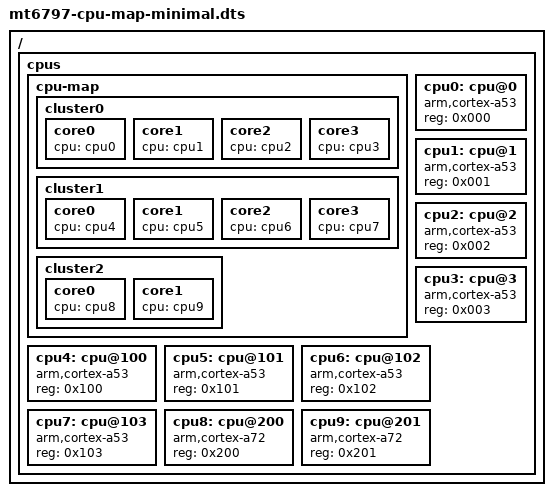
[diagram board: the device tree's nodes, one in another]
/dts-v1/;

/ {
	#address-cells = <2>;
	#size-cells = <2>;

	cpus {
		#address-cells = <1>;
		#size-cells = <0>;

		cpu-map {
			cluster0 {
				core0 { cpu = <&cpu0>; };
				core1 { cpu = <&cpu1>; };
				core2 { cpu = <&cpu2>; };
				core3 { cpu = <&cpu3>; };
			};
			cluster1 {
				core0 { cpu = <&cpu4>; };
				core1 { cpu = <&cpu5>; };
				core2 { cpu = <&cpu6>; };
				core3 { cpu = <&cpu7>; };
			};
			cluster2 {
				core0 { cpu = <&cpu8>; };
				core1 { cpu = <&cpu9>; };
			};
		};

		cpu0: cpu@0 {
			device_type = "cpu";
			compatible = "arm,cortex-a53";
			reg = <0x000>;
		};
		cpu1: cpu@1 {
			device_type = "cpu";
			compatible = "arm,cortex-a53";
			reg = <0x001>;
		};
		cpu2: cpu@2 {
			device_type = "cpu";
			compatible = "arm,cortex-a53";
			reg = <0x002>;
		};
		cpu3: cpu@3 {
			device_type = "cpu";
			compatible = "arm,cortex-a53";
			reg = <0x003>;
		};
		cpu4: cpu@100 {
			device_type = "cpu";
			compatible = "arm,cortex-a53";
			reg = <0x100>;
		};
		cpu5: cpu@101 {
			device_type = "cpu";
			compatible = "arm,cortex-a53";
			reg = <0x101>;
		};
		cpu6: cpu@102 {
			device_type = "cpu";
			compatible = "arm,cortex-a53";
			reg = <0x102>;
		};
		cpu7: cpu@103 {
			device_type = "cpu";
			compatible = "arm,cortex-a53";
			reg = <0x103>;
		};
		cpu8: cpu@200 {
			device_type = "cpu";
			compatible = "arm,cortex-a72";
			reg = <0x200>;
		};
		cpu9: cpu@201 {
			device_type = "cpu";
			compatible = "arm,cortex-a72";
			reg = <0x201>;
		};
	};
};
